# CY8C5868AXI_LP035 register map
File version: 0.1
Registers are 8-bit, read-write, no defined reset value unless marked. A register's access mark holds for its fields unless they carry their own. Offsets are from the block's base; [hi:lo] are bit positions; {n}, {i} and the like mark numbered series; 'fields as' and 'values as' point back to an identical list.

## pwmFan_1
Base 0x00000000
0x40006420 pwmFan_1_COMPARE_Reg_ — UDB.D0 - Assigned Compare Value
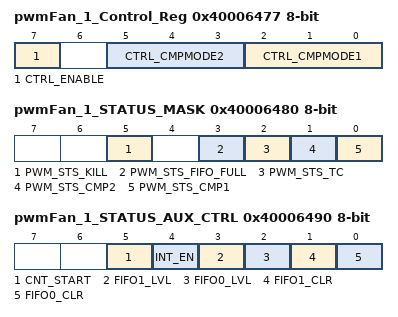
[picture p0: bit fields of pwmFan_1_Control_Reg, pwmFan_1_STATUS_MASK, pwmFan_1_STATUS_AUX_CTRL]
0x40006477 pwmFan_1_Control_Reg — UDB Control Register - Assigned Control Register Value
  [7] CTRL_ENABLE — Enable the PWM
  [5:3] CTRL_CMPMODE2 — Compare mode 2
  [2:0] CTRL_CMPMODE1 — Compare mode 1
0x40006480 pwmFan_1_STATUS_MASK — UDB Status bits Interrupt Mask Enable Register
  [5] PWM_STS_KILL ro — Enables the Interrupt on Kill
  [3] PWM_STS_FIFO_FULL ro — FIFO Full Status Mask
  [2] PWM_STS_TC ro — Enables the Interrupt on Terminal Count
  [1] PWM_STS_CMP2 ro — Enables the Interrupt on Compare 2
  [0] PWM_STS_CMP1 ro — Enables the Interrupt on Compare 1
0x40006490 pwmFan_1_STATUS_AUX_CTRL — UDB Auxilliary Control Register
  [5] CNT_START — FIFO0 clear
    0=E_CNT_START0 (Disable counter); 1=E_CNT_START1 (Enable counter)
  [4] INT_EN
    0=E_INT_EN0 (Interrupt disabled); 1=E_INT_EN1 (Interrupt enabled)
  [3] FIFO1_LVL — FIFO level
    0=E_FIFO_LVL_0 (FIFO LVL: input mode: FIFO not full; output mode: FIFO not empty); 1=E_FIFO_LVL_1 (FIFO LVL: input mode: FIFO at least 1/2 empty; output mode: FIFO at least 1/2 full)
  [2] FIFO0_LVL — FIFO level
    values as FIFO1_LVL
  [1] FIFO1_CLR — FIFO1 clear
    0=E_FIFO_CLR_0 (Normal FIFO operation); 1=E_FIFO_CLR_1 (Clear FIFO state)
  [0] FIFO0_CLR — FIFO0 clear
    values as FIFO1_CLR

## pwmFan_2
Base 0x00000000
0x40006421 pwmFan_2_COMPARE_Reg_ — UDB.D0 - Assigned Compare Value
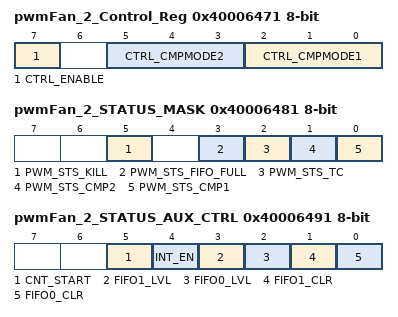
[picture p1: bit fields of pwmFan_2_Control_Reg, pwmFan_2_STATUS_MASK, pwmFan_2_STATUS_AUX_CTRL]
0x40006471 pwmFan_2_Control_Reg — UDB Control Register - Assigned Control Register Value
  [7] CTRL_ENABLE — Enable the PWM
  [5:3] CTRL_CMPMODE2 — Compare mode 2
  [2:0] CTRL_CMPMODE1 — Compare mode 1
0x40006481 pwmFan_2_STATUS_MASK — UDB Status bits Interrupt Mask Enable Register
  [5] PWM_STS_KILL ro — Enables the Interrupt on Kill
  [3] PWM_STS_FIFO_FULL ro — FIFO Full Status Mask
  [2] PWM_STS_TC ro — Enables the Interrupt on Terminal Count
  [1] PWM_STS_CMP2 ro — Enables the Interrupt on Compare 2
  [0] PWM_STS_CMP1 ro — Enables the Interrupt on Compare 1
0x40006491 pwmFan_2_STATUS_AUX_CTRL — UDB Auxilliary Control Register
  [5] CNT_START — FIFO0 clear
    0=E_CNT_START0 (Disable counter); 1=E_CNT_START1 (Enable counter)
  [4] INT_EN
    0=E_INT_EN0 (Interrupt disabled); 1=E_INT_EN1 (Interrupt enabled)
  [3] FIFO1_LVL — FIFO level
    0=E_FIFO_LVL_0 (FIFO LVL: input mode: FIFO not full; output mode: FIFO not empty); 1=E_FIFO_LVL_1 (FIFO LVL: input mode: FIFO at least 1/2 empty; output mode: FIFO at least 1/2 full)
  [2] FIFO0_LVL — FIFO level
    values as FIFO1_LVL
  [1] FIFO1_CLR — FIFO1 clear
    0=E_FIFO_CLR_0 (Normal FIFO operation); 1=E_FIFO_CLR_1 (Clear FIFO state)
  [0] FIFO0_CLR — FIFO0 clear
    values as FIFO1_CLR

## CAN_1
Base 0x00000000
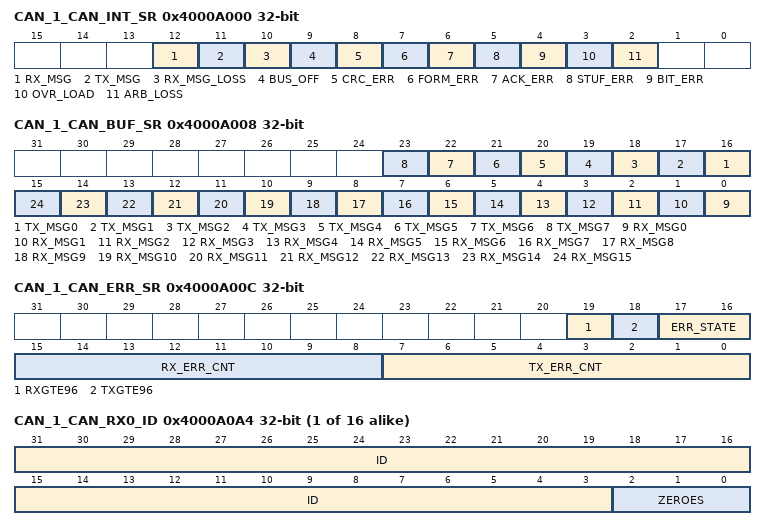
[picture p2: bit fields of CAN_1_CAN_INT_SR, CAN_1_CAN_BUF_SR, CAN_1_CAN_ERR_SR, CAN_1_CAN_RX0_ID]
0x4000A000 CAN_1_CAN_INT_SR 32-bit — The interrupt status register stores internal interrupt events. ? Once a bit is set it remains set until it is cleared by writing a '1' to it. ? The interrupt enable register has no effect on the interrupt status register. ? A pending interrupt occurs when the flag is set to '1'. To acknowledge an interrupt, set the flag to '1'
  [12] RX_MSG — Msg Recieved
  [11] TX_MSG — Tx msg Sent
  [10] RX_MSG_LOSS — Rx msg loss Interrupt
  [9] BUS_OFF — Bus Off State
  [8] CRC_ERR — CRC Error Interrupt
  [7] FORM_ERR — Form Error Interrupt
  [6] ACK_ERR — Ack Error Interrupt
  [5] STUF_ERR — Stuff Error Interrupt
  [4] BIT_ERR — Bit Error Interrupt
  [3] OVR_LOAD — Overload Interrupt
  [2] ARB_LOSS — Arbitration Loss
0x4000A008 CAN_1_CAN_BUF_SR 32-bit — These status indicators bundle the respective flags from all RxMessage and TxMessage buffers. ? Note All flags are read only. To acknowledge a MsgAv flag, the CPU must write to the respective RxMessage buffer
  [n+16] TX_MSG{n} (n=0..7) — Tx req Pending for Tx Msg{n}
  [n] RX_MSG{n} (n=0..15) — Rx Msg{n} Available
0x4000A00C CAN_1_CAN_ERR_SR 32-bit — Status indicators are provided to report the CAN controller error state, receive error count, and transmit error count. ? Special flags report error counter values equal to or in excess of 96 errors are available to indicate heavily disturbed bus situations. ? The transmitter error counter according to the CAN standard. When it is greater than 255 Decimal, it is fixed at 255 Decimal.
  [19] RXGTE96 — Rx Error Count is greater or equal to 96 Decimal
  [18] TXGTE96 — Tx Error Count is greater or equal to 96 Decimal
  [17:16] ERR_STATE — Error State of CAN node, 00 error active, 01 error passive, 1x bus off
  [15:8] RX_ERR_CNT — Rx error Count. When in bus-off state,this counter is used to count 128 groups of 11 recessive bits
  [7:0] TX_ERR_CNT — Tx error Count
{0x4000A024+0x10*i} CAN_1_CAN_TX{i}_ID 32-bit (i=0..7) — CAN Tx Msg Identifier
  [31:3] ID — Tx Msg Indentifier
{0x4000A028+0x10*i} CAN_1_CAN_TX{i}_DH 32-bit (i=0..7) — CAN Tx Msg Upper Data Bytes
  [31:0] DATA_HIGH — Upper Data Bytes
{0x4000A02C+0x10*i} CAN_1_CAN_TX{i}_DL 32-bit (i=0..7) — CAN Tx Msg Lower Data Bytes
  [31:0] DATA_LOW — Lower Data Bytes
{0x4000A0A4+0x20*i} CAN_1_CAN_RX{i}_ID 32-bit (i=0..15) — The register contains Rx Msg Identifier
  [31:3] ID — Rx Msg Indentifier
  [2:0] ZEROES — zeros
{0x4000A0A8+0x20*i} CAN_1_CAN_RX{i}_DH 32-bit (i=0..15) — The register contains the Rx Msg Upper Data Bytes
  [31:0] DATA_HIGH — Upper Data Bytes
{0x4000A0AC+0x20*i} CAN_1_CAN_RX{i}_DL 32-bit (i=0..15) — The register contains the Rx Msg Lover Data Bytes
  [31:0] DATA_LOW — Lower Data Bytes

## pwmAgitator_2
Base 0x00000000
0x4000642C pwmAgitator_2_COMPARE_Reg 16-bit — UDB.D0 - Assigned Compare Value
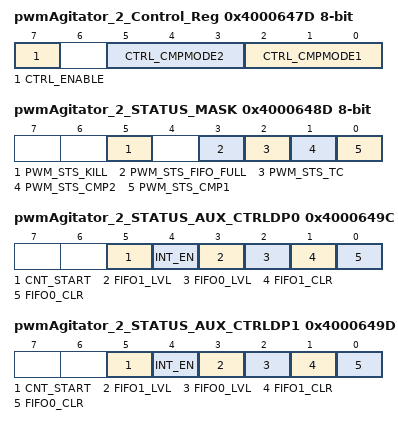
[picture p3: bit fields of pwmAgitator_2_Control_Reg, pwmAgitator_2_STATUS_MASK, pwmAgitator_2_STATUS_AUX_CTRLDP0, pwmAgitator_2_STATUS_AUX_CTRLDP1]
0x4000647D pwmAgitator_2_Control_Reg — UDB Control Register - Assigned Control Register Value
  [7] CTRL_ENABLE — Enable the PWM
  [5:3] CTRL_CMPMODE2 — Compare mode 2
  [2:0] CTRL_CMPMODE1 — Compare mode 1
0x4000648D pwmAgitator_2_STATUS_MASK — UDB Status bits Interrupt Mask Enable Register
  [5] PWM_STS_KILL ro — Enables the Interrupt on Kill
  [3] PWM_STS_FIFO_FULL ro — FIFO Full Status Mask
  [2] PWM_STS_TC ro — Enables the Interrupt on Terminal Count
  [1] PWM_STS_CMP2 ro — Enables the Interrupt on Compare 2
  [0] PWM_STS_CMP1 ro — Enables the Interrupt on Compare 1
0x4000649C pwmAgitator_2_STATUS_AUX_CTRLDP0 — UDB Auxilliary Control Register
  [5] CNT_START — FIFO0 clear
    0=E_CNT_START0 (Disable counter); 1=E_CNT_START1 (Enable counter)
  [4] INT_EN
    0=E_INT_EN0 (Interrupt disabled); 1=E_INT_EN1 (Interrupt enabled)
  [3] FIFO1_LVL — FIFO level
    0=E_FIFO_LVL_0 (FIFO LVL: input mode: FIFO not full; output mode: FIFO not empty); 1=E_FIFO_LVL_1 (FIFO LVL: input mode: FIFO at least 1/2 empty; output mode: FIFO at least 1/2 full)
  [2] FIFO0_LVL — FIFO level
    values as FIFO1_LVL
  [1] FIFO1_CLR — FIFO1 clear
    0=E_FIFO_CLR_0 (Normal FIFO operation); 1=E_FIFO_CLR_1 (Clear FIFO state)
  [0] FIFO0_CLR — FIFO0 clear
    values as FIFO1_CLR
0x4000649D pwmAgitator_2_STATUS_AUX_CTRLDP1 — UDB Auxilliary Control Register
  fields as pwmAgitator_2_STATUS_AUX_CTRLDP0
